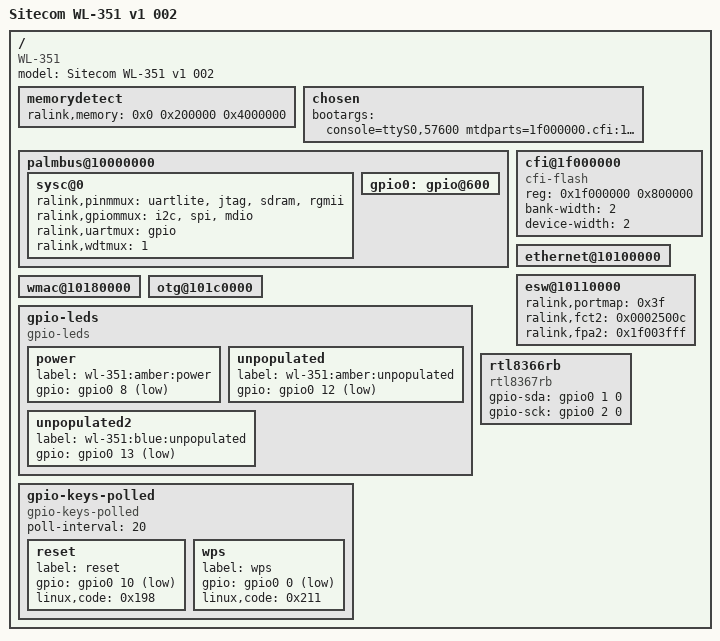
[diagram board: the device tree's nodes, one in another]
/dts-v1/;

/include/ "rt3050.dtsi"

/ {
	#address-cells = <1>;
	#size-cells = <1>;
	compatible = "WL-351", "ralink,rt3052-soc";
	model = "Sitecom WL-351 v1 002";

	memorydetect {
		ralink,memory = <0x0 0x200000 0x4000000>;
	};


	chosen {
		bootargs = "console=ttyS0,57600 mtdparts=1f000000.cfi:192k(u-boot)ro,64k(u-boot-env)ro,64k(factory)ro,3776k@0x50000(firmware)";
	};

	palmbus@10000000 {
		sysc@0 {
			ralink,pinmmux = "uartlite", "jtag", "sdram", "rgmii";
			ralink,gpiommux = "i2c", "spi", "mdio";
			ralink,uartmux = "gpio";
			ralink,wdtmux = <1>;
		};

		gpio0: gpio@600 {
			status = "okay";
		};

	};

	cfi@1f000000 {
		compatible = "cfi-flash";
		reg = <0x1f000000 0x800000>;

		bank-width = <2>;
		device-width = <2>;
		#address-cells = <1>;
		#size-cells = <1>;
	};

	ethernet@10100000 {
		status = "okay";
	};

	esw@10110000 {
		status = "okay";
		ralink,portmap = <0x3f>;
		ralink,fct2 = <0x0002500c>;
		/*
		 * ext phy base addr 31, rx/tx clock skew 0,
		 * turbo mii off, rgmi 3.3v off, port 5 polling off
		 * port5: enabled, gige, full-duplex, rx/tx-flow-control
		 * port6: enabled, gige, full-duplex, rx/tx-flow-control
		*/
		ralink,fpa2 = <0x1f003fff>;
	};

	wmac@10180000 {
		status = "okay";
	};

	otg@101c0000 {
		status = "okay";
	};

	gpio-leds {
		compatible = "gpio-leds";
		power {
			label = "wl-351:amber:power";
			gpio = <&gpio0 8 1>;
		};
		unpopulated {
			label = "wl-351:amber:unpopulated";
			gpio = <&gpio0 12 1>;
		};
		unpopulated2 {
			label = "wl-351:blue:unpopulated";
			gpio = <&gpio0 13 1>;
		};
	};

	gpio-keys-polled {
		compatible = "gpio-keys-polled";
		#address-cells = <1>;
		#size-cells = <0>;
		poll-interval = <20>;
		reset {
			label = "reset";
			gpio = <&gpio0 10 1>;
			linux,code = <0x198>;
		};
		wps {
			label = "wps";
			gpio = <&gpio0 0 1>;
			linux,code = <0x211>;
		};
	};

	rtl8366rb {
		compatible = "rtl8367rb";
		gpio-sda = <&gpio0 1 0>;
		gpio-sck = <&gpio0 2 0>;
	};
};
